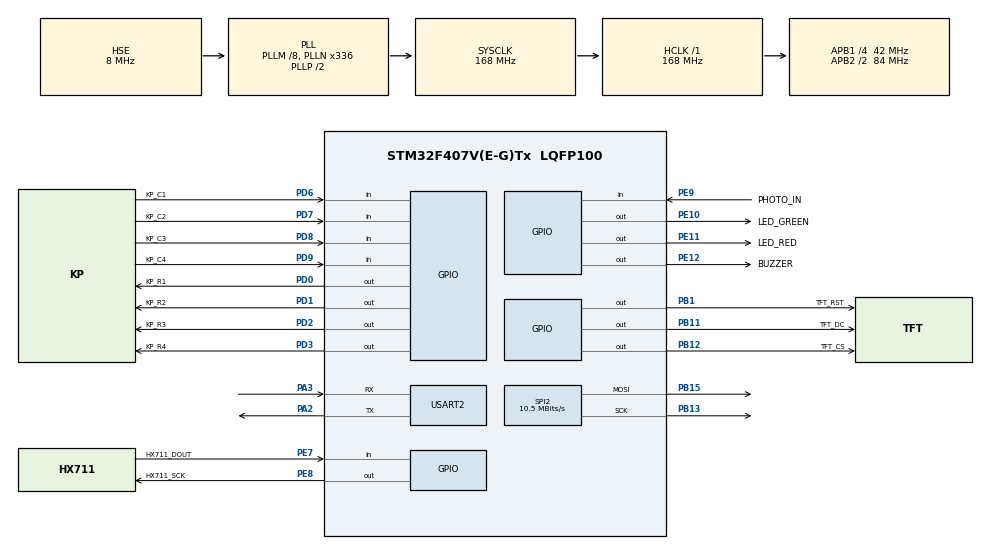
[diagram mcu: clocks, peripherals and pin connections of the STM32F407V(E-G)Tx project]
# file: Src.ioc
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FREERTOS.Tasks01=defaultTask,24,128,StartDefaultTask,Default,NULL,Dynamic,NULL,NULL
FREERTOS.configTOTAL_HEAP_SIZE=32768
Mcu.Family=STM32F4
Mcu.Name=STM32F407V(E-G)Tx
Mcu.Package=LQFP100
NVIC.PriorityGroup=NVIC_PRIORITYGROUP_4
NVIC.TIM7_IRQn=true\:15\:0\:false\:false\:true\:false\:false\:true\:true
NVIC.TimeBase=TIM7_IRQn
NVIC.TimeBaseIP=TIM7
PA13.Mode=Serial_Wire
PA13.Signal=SYS_JTMS-SWDIO
PA14.Mode=Serial_Wire
PA14.Signal=SYS_JTCK-SWCLK
PA2.Mode=Asynchronous
PA2.Signal=USART2_TX
PA3.Mode=Asynchronous
PA3.Signal=USART2_RX
PB1.GPIO_Label=TFT_RST
PB1.PinState=GPIO_PIN_SET
PB1.Signal=GPIO_Output
PB11.GPIO_Label=TFT_DC
PB11.GPIO_Speed=GPIO_SPEED_FREQ_HIGH
PB11.Signal=GPIO_Output
PB12.GPIO_Label=TFT_CS
PB12.GPIO_Speed=GPIO_SPEED_FREQ_HIGH
PB12.PinState=GPIO_PIN_SET
PB12.Signal=GPIO_Output
PB13.Mode=TX_Only_Simplex_Unidirect_Master
PB13.Signal=SPI2_SCK
PB15.Mode=TX_Only_Simplex_Unidirect_Master
PB15.Signal=SPI2_MOSI
PD0.GPIO_Label=KP_R1
PD0.GPIO_ModeDefaultOutputPP=GPIO_MODE_OUTPUT_OD
PD0.PinState=GPIO_PIN_SET
PD0.Signal=GPIO_Output
PD1.GPIO_Label=KP_R2
PD1.GPIO_ModeDefaultOutputPP=GPIO_MODE_OUTPUT_OD
PD1.PinState=GPIO_PIN_SET
PD1.Signal=GPIO_Output
PD2.GPIO_Label=KP_R3
PD2.GPIO_ModeDefaultOutputPP=GPIO_MODE_OUTPUT_OD
PD2.PinState=GPIO_PIN_SET
PD2.Signal=GPIO_Output
PD3.GPIO_Label=KP_R4
PD3.GPIO_ModeDefaultOutputPP=GPIO_MODE_OUTPUT_OD
PD3.PinState=GPIO_PIN_SET
PD3.Signal=GPIO_Output
PD6.GPIO_Label=KP_C1
PD6.GPIO_PuPd=GPIO_PULLUP
PD6.Signal=GPIO_Input
PD7.GPIO_Label=KP_C2
PD7.GPIO_PuPd=GPIO_PULLUP
PD7.Signal=GPIO_Input
PD8.GPIO_Label=KP_C3
PD8.GPIO_PuPd=GPIO_PULLUP
PD8.Signal=GPIO_Input
PD9.GPIO_Label=KP_C4
PD9.GPIO_PuPd=GPIO_PULLUP
PD9.Signal=GPIO_Input
PE10.GPIO_Label=LED_GREEN
PE10.Signal=GPIO_Output
PE11.GPIO_Label=LED_RED
PE11.Signal=GPIO_Output
PE12.GPIO_Label=BUZZER
PE12.Signal=GPIO_Output
PE7.GPIO_Label=HX711_DOUT
PE7.Signal=GPIO_Input
PE8.GPIO_Label=HX711_SCK
PE8.Signal=GPIO_Output
PE9.GPIO_Label=PHOTO_IN
PE9.GPIO_PuPd=GPIO_PULLUP
PE9.Signal=GPIO_Input
PH0-OSC_IN.Mode=HSE-External-Oscillator
PH0-OSC_IN.Signal=RCC_OSC_IN
PH1-OSC_OUT.Mode=HSE-External-Oscillator
PH1-OSC_OUT.Signal=RCC_OSC_OUT
ProjectManager.HeapSize=0x200
ProjectManager.StackSize=0x400
ProjectManager.TargetToolchain=CMake
RCC.48MHZClocksFreq_Value=48000000
RCC.AHBFreq_Value=168000000
RCC.APB1CLKDivider=RCC_HCLK_DIV4
RCC.APB1Freq_Value=42000000
RCC.APB1TimFreq_Value=84000000
RCC.APB2CLKDivider=RCC_HCLK_DIV2
RCC.APB2Freq_Value=84000000
RCC.APB2TimFreq_Value=168000000
RCC.CortexFreq_Value=168000000
RCC.HCLKFreq_Value=168000000
RCC.HSE_VALUE=8000000
RCC.HSI_VALUE=16000000
RCC.LSE_VALUE=32768
RCC.PLLM=8
RCC.PLLN=336
RCC.PLLQ=7
RCC.PLLSourceVirtual=RCC_PLLSOURCE_HSE
RCC.SYSCLKFreq_VALUE=168000000
RCC.SYSCLKSource=RCC_SYSCLKSOURCE_PLLCLK
RCC.VCOOutputFreq_Value=336000000
SPI2.BaudRatePrescaler=SPI_BAUDRATEPRESCALER_4
SPI2.CalculateBaudRate=10.5 MBits/s
SPI2.Direction=SPI_DIRECTION_2LINES
SPI2.Mode=SPI_MODE_MASTER
SPI2.VirtualType=VM_MASTER
USART2.VirtualMode=VM_ASYNC
VP_FREERTOS_VS_CMSIS_V2.Mode=CMSIS_V2
VP_SYS_VS_tim7.Mode=TIM7
board=custom

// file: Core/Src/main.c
/* USER CODE BEGIN Header */
/**
  ******************************************************************************
  * @file           : main.c
  * @brief          : Main program body
  ******************************************************************************
  * @attention
  *
  * Copyright (c) 2026 STMicroelectronics.
  * All rights reserved.
  *
  * This software is licensed under terms that can be found in the LICENSE file
  * in the root directory of this software component.
  * If no LICENSE file comes with this software, it is provided AS-IS.
  *
  ******************************************************************************
  */
/* USER CODE END Header */
#include "main.h"
#include "cmsis_os.h"

/* USER CODE BEGIN Includes */
#include "app_main.h"
/* USER CODE END Includes */

SPI_HandleTypeDef hspi2;

UART_HandleTypeDef huart2;

/* Definitions for defaultTask */
osThreadId_t defaultTaskHandle;
const osThreadAttr_t defaultTask_attributes = {
  .name = "defaultTask",
  .stack_size = 128 * 4,
  .priority = (osPriority_t) osPriorityNormal,
};

void SystemClock_Config(void);
static void MX_GPIO_Init(void);
static void MX_SPI2_Init(void);
static void MX_USART2_UART_Init(void);
void StartDefaultTask(void *argument);

int main(void)
{

  /* MCU Configuration--------------------------------------------------------*/

  /* Reset of all peripherals, Initializes the Flash interface and the Systick. */
  HAL_Init();

  /* Configure the system clock */
  SystemClock_Config();

  /* Initialize all configured peripherals */
  MX_GPIO_Init();
  MX_SPI2_Init();
  MX_USART2_UART_Init();

  /* Init scheduler */
  osKernelInitialize();

  /* Create the thread(s) */
  /* creation of defaultTask */
  defaultTaskHandle = osThreadNew(StartDefaultTask, NULL, &defaultTask_attributes);

  /* USER CODE BEGIN RTOS_THREADS */
  /* * Tao toan bo queue va 5 task cua ung dung (App/Tasks/app_main.c). */
  App_Init();
  /* USER CODE END RTOS_THREADS */

  /* Start scheduler */
  osKernelStart();

  /* We should never get here as control is now taken by the scheduler */

  /* Infinite loop */
  while (1)
  {

  }
}

void SystemClock_Config(void)
{
  RCC_OscInitTypeDef RCC_OscInitStruct = {0};
  RCC_ClkInitTypeDef RCC_ClkInitStruct = {0};

  /** Configure the main internal regulator output voltage
  */
  __HAL_RCC_PWR_CLK_ENABLE();
  __HAL_PWR_VOLTAGESCALING_CONFIG(PWR_REGULATOR_VOLTAGE_SCALE1);

  /** Initializes the RCC Oscillators according to the specified parameters
  * in the RCC_OscInitTypeDef structure.
  */
  RCC_OscInitStruct.OscillatorType = RCC_OSCILLATORTYPE_HSE;
  RCC_OscInitStruct.HSEState = RCC_HSE_ON;
  RCC_OscInitStruct.PLL.PLLState = RCC_PLL_ON;
  RCC_OscInitStruct.PLL.PLLSource = RCC_PLLSOURCE_HSE;
  RCC_OscInitStruct.PLL.PLLM = 8;
  RCC_OscInitStruct.PLL.PLLN = 336;
  RCC_OscInitStruct.PLL.PLLP = RCC_PLLP_DIV2;
  RCC_OscInitStruct.PLL.PLLQ = 7;
  if (HAL_RCC_OscConfig(&RCC_OscInitStruct) != HAL_OK)
  {
    Error_Handler();
  }

  /** Initializes the CPU, AHB and APB buses clocks
  */
  RCC_ClkInitStruct.ClockType = RCC_CLOCKTYPE_HCLK|RCC_CLOCKTYPE_SYSCLK
                              |RCC_CLOCKTYPE_PCLK1|RCC_CLOCKTYPE_PCLK2;
  RCC_ClkInitStruct.SYSCLKSource = RCC_SYSCLKSOURCE_PLLCLK;
  RCC_ClkInitStruct.AHBCLKDivider = RCC_SYSCLK_DIV1;
  RCC_ClkInitStruct.APB1CLKDivider = RCC_HCLK_DIV4;
  RCC_ClkInitStruct.APB2CLKDivider = RCC_HCLK_DIV2;

  if (HAL_RCC_ClockConfig(&RCC_ClkInitStruct, FLASH_LATENCY_5) != HAL_OK)
  {
    Error_Handler();
  }
}

static void MX_SPI2_Init(void)
{

  /* SPI2 parameter configuration*/
  hspi2.Instance = SPI2;
  hspi2.Init.Mode = SPI_MODE_MASTER;
  hspi2.Init.Direction = SPI_DIRECTION_2LINES;
  hspi2.Init.DataSize = SPI_DATASIZE_8BIT;
  hspi2.Init.CLKPolarity = SPI_POLARITY_LOW;
  hspi2.Init.CLKPhase = SPI_PHASE_1EDGE;
  hspi2.Init.NSS = SPI_NSS_SOFT;
  hspi2.Init.BaudRatePrescaler = SPI_BAUDRATEPRESCALER_4;
  hspi2.Init.FirstBit = SPI_FIRSTBIT_MSB;
  hspi2.Init.TIMode = SPI_TIMODE_DISABLE;
  hspi2.Init.CRCCalculation = SPI_CRCCALCULATION_DISABLE;
  hspi2.Init.CRCPolynomial = 10;
  if (HAL_SPI_Init(&hspi2) != HAL_OK)
  {
    Error_Handler();
  }

}

static void MX_USART2_UART_Init(void)
{

  huart2.Instance = USART2;
  huart2.Init.BaudRate = 115200;
  huart2.Init.WordLength = UART_WORDLENGTH_8B;
  huart2.Init.StopBits = UART_STOPBITS_1;
  huart2.Init.Parity = UART_PARITY_NONE;
  huart2.Init.Mode = UART_MODE_TX_RX;
  huart2.Init.HwFlowCtl = UART_HWCONTROL_NONE;
  huart2.Init.OverSampling = UART_OVERSAMPLING_16;
  if (HAL_UART_Init(&huart2) != HAL_OK)
  {
    Error_Handler();
  }

}

static void MX_GPIO_Init(void)
{
  GPIO_InitTypeDef GPIO_InitStruct = {0};

  /* GPIO Ports Clock Enable */
  __HAL_RCC_GPIOE_CLK_ENABLE();
  __HAL_RCC_GPIOH_CLK_ENABLE();
  __HAL_RCC_GPIOA_CLK_ENABLE();
  __HAL_RCC_GPIOB_CLK_ENABLE();
  __HAL_RCC_GPIOD_CLK_ENABLE();

  /*Configure GPIO pin Output Level */
  HAL_GPIO_WritePin(GPIOE, HX711_SCK_Pin|LED_GREEN_Pin|LED_RED_Pin|BUZZER_Pin, GPIO_PIN_RESET);

  /*Configure GPIO pin Output Level */
  HAL_GPIO_WritePin(GPIOB, TFT_RST_Pin|TFT_CS_Pin, GPIO_PIN_SET);

  /*Configure GPIO pin Output Level */
  HAL_GPIO_WritePin(TFT_DC_GPIO_Port, TFT_DC_Pin, GPIO_PIN_RESET);

  /*Configure GPIO pin Output Level */
  HAL_GPIO_WritePin(GPIOD, KP_R1_Pin|KP_R2_Pin|KP_R3_Pin|KP_R4_Pin, GPIO_PIN_SET);

  /*Configure GPIO pin : HX711_DOUT_Pin */
  GPIO_InitStruct.Pin = HX711_DOUT_Pin;
  GPIO_InitStruct.Mode = GPIO_MODE_INPUT;
  GPIO_InitStruct.Pull = GPIO_NOPULL;
  HAL_GPIO_Init(HX711_DOUT_GPIO_Port, &GPIO_InitStruct);

  /*Configure GPIO pins : HX711_SCK_Pin LED_GREEN_Pin LED_RED_Pin BUZZER_Pin */
  GPIO_InitStruct.Pin = HX711_SCK_Pin|LED_GREEN_Pin|LED_RED_Pin|BUZZER_Pin;
  GPIO_InitStruct.Mode = GPIO_MODE_OUTPUT_PP;
  GPIO_InitStruct.Pull = GPIO_NOPULL;
  GPIO_InitStruct.Speed = GPIO_SPEED_FREQ_LOW;
  HAL_GPIO_Init(GPIOE, &GPIO_InitStruct);

  /*Configure GPIO pin : PHOTO_IN_Pin */
  GPIO_InitStruct.Pin = PHOTO_IN_Pin;
  GPIO_InitStruct.Mode = GPIO_MODE_INPUT;
  GPIO_InitStruct.Pull = GPIO_PULLUP;
  HAL_GPIO_Init(PHOTO_IN_GPIO_Port, &GPIO_InitStruct);

  /*Configure GPIO pin : TFT_RST_Pin */
  GPIO_InitStruct.Pin = TFT_RST_Pin;
  GPIO_InitStruct.Mode = GPIO_MODE_OUTPUT_PP;
  GPIO_InitStruct.Pull = GPIO_NOPULL;
  GPIO_InitStruct.Speed = GPIO_SPEED_FREQ_LOW;
  HAL_GPIO_Init(TFT_RST_GPIO_Port, &GPIO_InitStruct);

  /*Configure GPIO pins : TFT_DC_Pin TFT_CS_Pin */
  GPIO_InitStruct.Pin = TFT_DC_Pin|TFT_CS_Pin;
  GPIO_InitStruct.Mode = GPIO_MODE_OUTPUT_PP;
  GPIO_InitStruct.Pull = GPIO_NOPULL;
  GPIO_InitStruct.Speed = GPIO_SPEED_FREQ_HIGH;
  HAL_GPIO_Init(GPIOB, &GPIO_InitStruct);

  /*Configure GPIO pins : KP_C3_Pin KP_C4_Pin KP_C1_Pin KP_C2_Pin */
  GPIO_InitStruct.Pin = KP_C3_Pin|KP_C4_Pin|KP_C1_Pin|KP_C2_Pin;
  GPIO_InitStruct.Mode = GPIO_MODE_INPUT;
  GPIO_InitStruct.Pull = GPIO_PULLUP;
  HAL_GPIO_Init(GPIOD, &GPIO_InitStruct);

  /*Configure GPIO pins : KP_R1_Pin KP_R2_Pin KP_R3_Pin KP_R4_Pin */
  GPIO_InitStruct.Pin = KP_R1_Pin|KP_R2_Pin|KP_R3_Pin|KP_R4_Pin;
  GPIO_InitStruct.Mode = GPIO_MODE_OUTPUT_OD;
  GPIO_InitStruct.Pull = GPIO_NOPULL;
  GPIO_InitStruct.Speed = GPIO_SPEED_FREQ_LOW;
  HAL_GPIO_Init(GPIOD, &GPIO_InitStruct);

}

void StartDefaultTask(void *argument)
{
  /* USER CODE BEGIN 5 */
  /* * Task mac dinh cua CubeMX khong dung toi: cac task ung dung duoc tao
   *   trong App_Init(). Ket thuc task nay de tra lai bo nho stack. */
  osThreadExit();
  /* USER CODE END 5 */
}

void HAL_TIM_PeriodElapsedCallback(TIM_HandleTypeDef *htim)
{
  if (htim->Instance == TIM7)
  {
    HAL_IncTick();
  }
}

void Error_Handler(void)
{
  __disable_irq();
  while (1)
  {
  }
}
